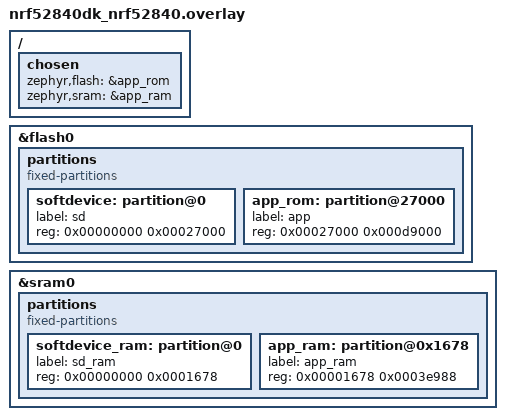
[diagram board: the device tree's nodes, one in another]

&flash0 {
	partitions {
		compatible = "fixed-partitions";
		#address-cells = <1>;
		#size-cells = <1>;
		softdevice: partition@0 {
			label = "sd";
			reg = <0x00000000 0x00027000>;
		};
		app_rom: partition@27000 {
			label = "app";
			reg = <0x00027000 0x000d9000>;
		};
	};
};

&sram0 {
	partitions {
		compatible = "fixed-partitions";
		#address-cells = <1>;
		#size-cells = <1>;
		softdevice_ram: partition@0 {
			label = "sd_ram";
			reg = <0x00000000 0x0001678>;
		};
		app_ram: partition@0x1678 {
			label = "app_ram";
			reg = <0x00001678 0x0003e988>;
		};
	};
};


/ {
	chosen {
		zephyr,flash = &app_rom;
		zephyr,sram = &app_ram;
	};
};
